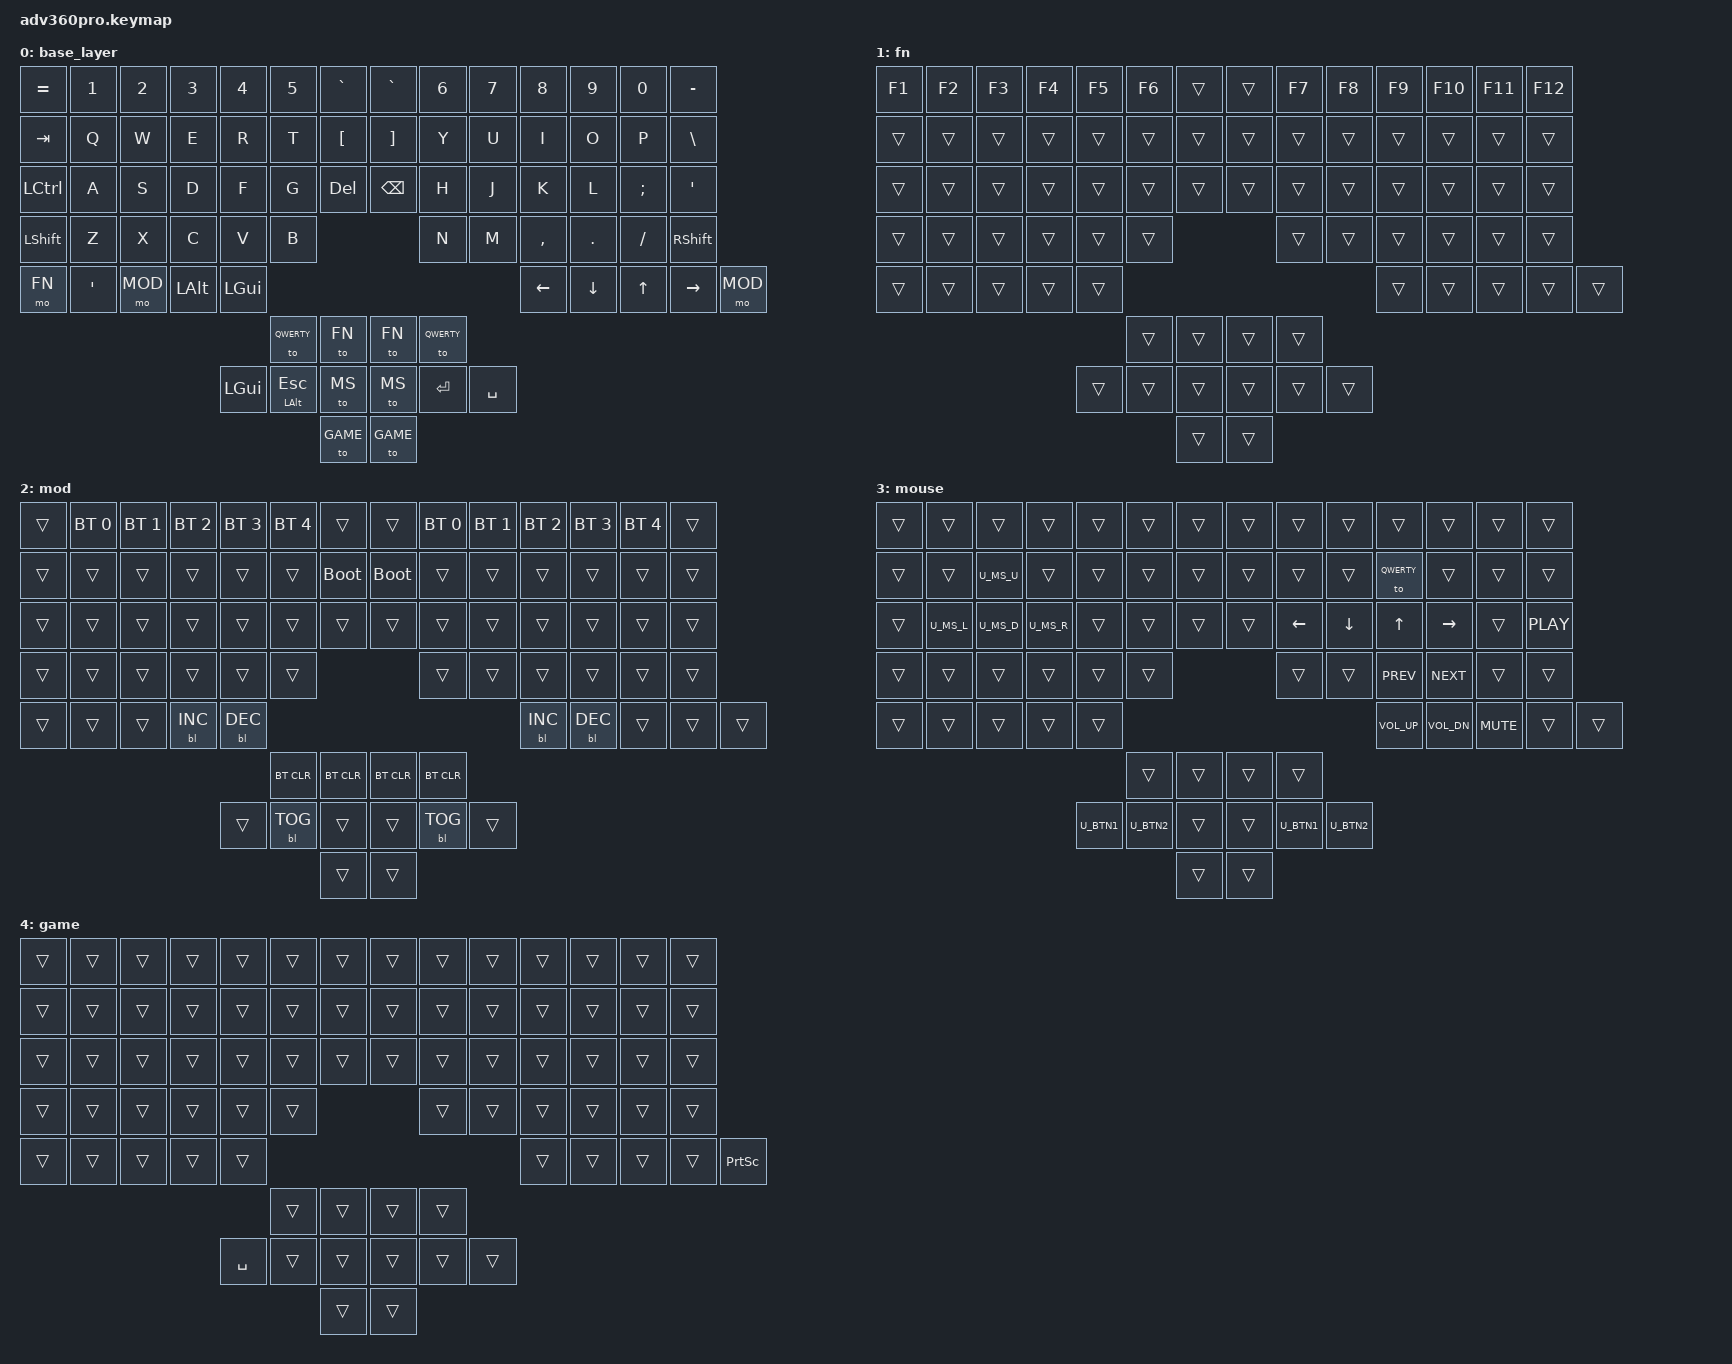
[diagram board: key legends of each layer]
#include <behaviors.dtsi>
#include <dt-bindings/zmk/keys.h>
#include <dt-bindings/zmk/bt.h>
#include <dt-bindings/zmk/outputs.h>
#include <dt-bindings/zmk/rgb.h>
#include <dt-bindings/zmk/backlight.h>

/* definitions for mouse layer */
#include "mouse.dtsi"

#define ___ &trans

#define QWERTY 0
#define FN 1
#define MOD 2
#define MS 3
#define GAME 4

/ {
    /* remove unused keys from layout and move thumb cluster to bottom */
    chosen {
        zmk,matrix_transform = &urobs_transform;
    };

    keymap {
        compatible = "zmk,keymap";

        base_layer {
            bindings = <
                &kp EQUAL &kp N1    &kp N2    &kp N3    &kp N4    &kp N5    &kp GRAVE      &kp GRAVE &kp N6    &kp N7    &kp N8    &kp N9    &kp N0    &kp MINUS
                &kp TAB   &kp Q     &kp W     &kp E     &kp R     &kp T     &kp LEFT_BRACKET &kp RIGHT_BRACKET   &kp Y     &kp U     &kp I     &kp O     &kp P     &kp BSLH
                &kp LCTRL &kp A     &kp S     &kp D     &kp F     &kp G     &kp DEL    &kp BACKSPACE &kp H     &kp J     &kp K     &kp L     &kp SEMI  &kp SQT
                &kp LSHFT &kp Z     &kp X     &kp C     &kp V     &kp B                              &kp N     &kp M     &kp COMMA &kp DOT   &kp FSLH  &kp RSHFT
                &mo FN    &kp SINGLE_QUOTE &mo MOD &kp LEFT_ALT &kp LEFT_GUI                                             &kp LEFT  &kp DOWN  &kp UP &kp RIGHT &mo MOD
                                                                  &to QWERTY &to FN        &to FN    &to QWERTY
                                                        &kp LEFT_GUI  &mt LALT ESC &to MS       &to MS    &kp ENTER &kp SPACE
                                                                            &to GAME       &to GAME
            >;
        };

        fn {
            bindings = <
                &kp F1    &kp F2    &kp F3    &kp F4    &kp F5    &kp F6    ___            ___       &kp F7    &kp F8    &kp F9    &kp F10   &kp F11   &kp F12
                ___       ___       ___       ___       ___       ___       ___            ___       ___       ___       ___       ___       ___       ___
                ___       ___       ___       ___       ___       ___       ___            ___       ___       ___       ___       ___       ___       ___
                ___       ___       ___       ___       ___       ___                                ___       ___       ___       ___       ___       ___
                ___       ___       ___       ___       ___                                                    ___       ___       ___       ___       ___
                                                                  ___       ___            ___       ___
                                                        ___       ___       ___            ___       ___       ___
                                                                            ___            ___
            >;
        };

        mod {
            bindings = <
                ___       &bt BT_SEL 0 &bt BT_SEL 1 &bt BT_SEL 2 &bt BT_SEL 3 &bt BT_SEL 4 ___              ___         &bt BT_SEL 0 &bt BT_SEL 1     &bt BT_SEL 2 &bt BT_SEL 3 &bt BT_SEL 4 ___
                ___       ___          ___          ___          ___          ___          &bootloader      &bootloader ___          ___              ___          ___          ___          ___
                ___       ___          ___          ___          ___          ___          ___              ___         ___          ___              ___          ___          ___          ___
                ___       ___          ___          ___          ___          ___                                       ___          ___              ___          ___          ___          ___
                ___       ___          ___          &bl BL_INC   &bl BL_DEC                                                          &bl BL_INC       &bl BL_DEC   ___          ___          ___
                                                                              &bt BT_CLR   &bt BT_CLR       &bt BT_CLR  &bt BT_CLR
                                                                 ___          &bl BL_TOG   ___              ___         &bl BL_TOG   ___
                                                                                           ___              ___
            >;
        };

        mouse {
            bindings = <
                ___       ___       ___       ___       ___       ___       ___            ___       ___       ___       ___       ___       ___       ___
                ___       ___       U_MS_U    ___       ___       ___       ___            ___       ___       ___       &to QWERTY ___      ___       ___
                ___       U_MS_L    U_MS_D    U_MS_R    ___       ___       ___            ___       &kp LEFT  &kp DOWN  &kp UP    &kp RIGHT ___       &kp C_PLAY
                ___       ___       ___       ___       ___       ___                                ___       ___       &kp C_PREV &kp C_NEXT ___     ___
                ___       ___       ___       ___       ___                                                    &kp C_VOL_UP &kp C_VOL_DN &kp C_MUTE ___  ___
                                                                  ___       ___            ___       ___
                                                        U_BTN1    U_BTN2    ___            ___       U_BTN1    U_BTN2
                                                                            ___            ___
            >;
        };

        game {
            bindings = <
                ___       ___       ___       ___       ___       ___       ___            ___       ___       ___       ___       ___       ___       ___
                ___       ___       ___       ___       ___       ___       ___            ___       ___       ___       ___       ___       ___       ___
                ___       ___       ___       ___       ___       ___       ___            ___       ___       ___       ___       ___       ___       ___
                ___       ___       ___       ___       ___       ___                                ___       ___       ___       ___       ___       ___
                ___       ___       ___       ___       ___                                                    ___       ___       ___       ___       &kp PRINTSCREEN
                                                                  ___       ___            ___       ___
                                                        &kp SPACE ___       ___            ___       ___       ___
                                                                            ___            ___
            >;
        };

    };

};

